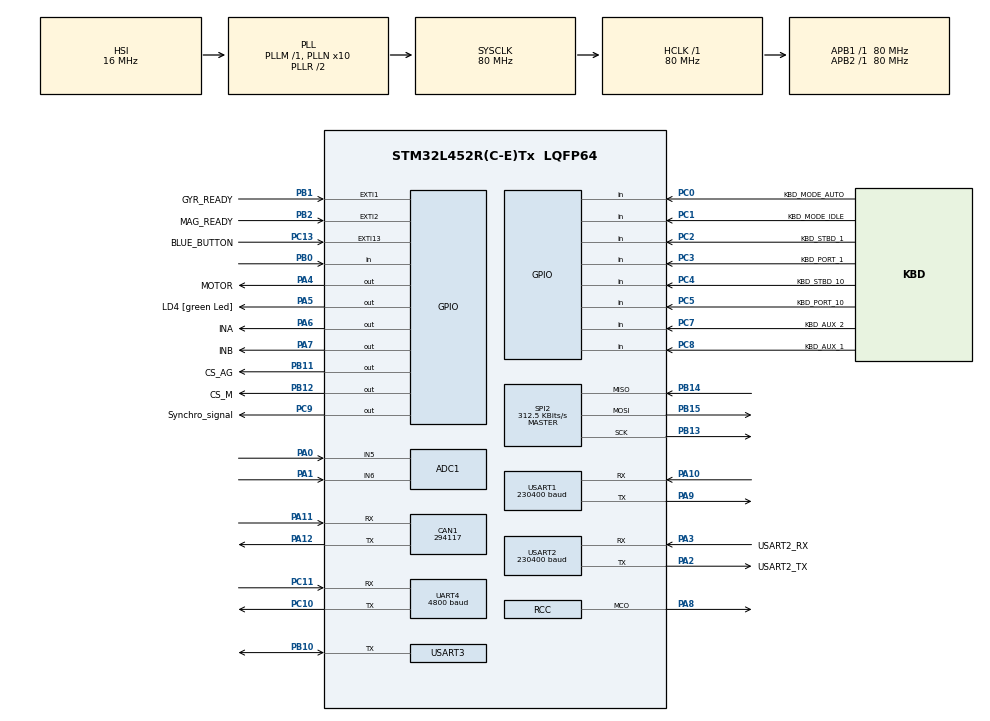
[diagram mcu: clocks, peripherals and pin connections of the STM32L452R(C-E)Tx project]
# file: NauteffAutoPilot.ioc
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ADC1.Channel-1\#ChannelRegularConversion=ADC_CHANNEL_5
ADC1.Channel-2\#ChannelRegularConversion=ADC_CHANNEL_6
ADC1.DMAContinuousRequests=ENABLE
ADC1.EOCSelection=ADC_EOC_SEQ_CONV
ADC1.ExternalTrigConv=ADC_EXTERNALTRIG_T3_TRGO
ADC1.NbrOfConversion=2
ADC1.NbrOfConversionFlag=1
ADC1.OffsetNumber-1\#ChannelRegularConversion=ADC_OFFSET_NONE
ADC1.OffsetNumber-2\#ChannelRegularConversion=ADC_OFFSET_NONE
ADC1.Rank-1\#ChannelRegularConversion=1
ADC1.Rank-2\#ChannelRegularConversion=2
ADC1.SamplingTime-1\#ChannelRegularConversion=ADC_SAMPLETIME_47CYCLES_5
ADC1.SamplingTime-2\#ChannelRegularConversion=ADC_SAMPLETIME_47CYCLES_5
ADC1.master=1
CAN1.BS1=CAN_BS1_8TQ
CAN1.BS2=CAN_BS2_8TQ
CAN1.CalculateBaudRate=294117
CAN1.CalculateTimeBit=3400
CAN1.CalculateTimeQuantum=200.0
Dma.ADC1.4.Direction=DMA_PERIPH_TO_MEMORY
Dma.ADC1.4.Instance=DMA1_Channel1
Dma.ADC1.4.MemDataAlignment=DMA_MDATAALIGN_HALFWORD
Dma.ADC1.4.MemInc=DMA_MINC_ENABLE
Dma.ADC1.4.Mode=DMA_CIRCULAR
Dma.ADC1.4.PeriphDataAlignment=DMA_PDATAALIGN_HALFWORD
Dma.ADC1.4.PeriphInc=DMA_PINC_DISABLE
Dma.ADC1.4.Priority=DMA_PRIORITY_LOW
Dma.Request0=USART2_RX
Dma.Request1=USART2_TX
Dma.Request2=USART1_RX
Dma.Request3=USART1_TX
Dma.Request4=ADC1
Dma.Request5=SPI2_RX
Dma.Request6=SPI2_TX
Dma.Request7=UART4_RX
Dma.Request8=UART4_TX
Dma.SPI2_RX.5.Direction=DMA_PERIPH_TO_MEMORY
Dma.SPI2_RX.5.Instance=DMA1_Channel4
Dma.SPI2_RX.5.MemDataAlignment=DMA_MDATAALIGN_BYTE
Dma.SPI2_RX.5.MemInc=DMA_MINC_ENABLE
Dma.SPI2_RX.5.Mode=DMA_NORMAL
Dma.SPI2_RX.5.PeriphDataAlignment=DMA_PDATAALIGN_BYTE
Dma.SPI2_RX.5.PeriphInc=DMA_PINC_DISABLE
Dma.SPI2_RX.5.Priority=DMA_PRIORITY_LOW
Dma.SPI2_TX.6.Direction=DMA_MEMORY_TO_PERIPH
Dma.SPI2_TX.6.Instance=DMA1_Channel5
Dma.SPI2_TX.6.MemDataAlignment=DMA_MDATAALIGN_BYTE
Dma.SPI2_TX.6.MemInc=DMA_MINC_ENABLE
Dma.SPI2_TX.6.Mode=DMA_NORMAL
Dma.SPI2_TX.6.PeriphDataAlignment=DMA_PDATAALIGN_BYTE
Dma.SPI2_TX.6.PeriphInc=DMA_PINC_DISABLE
Dma.SPI2_TX.6.Priority=DMA_PRIORITY_LOW
Dma.UART4_RX.7.Direction=DMA_PERIPH_TO_MEMORY
Dma.UART4_RX.7.Instance=DMA2_Channel5
Dma.UART4_RX.7.MemDataAlignment=DMA_MDATAALIGN_BYTE
Dma.UART4_RX.7.MemInc=DMA_MINC_ENABLE
Dma.UART4_RX.7.Mode=DMA_NORMAL
Dma.UART4_RX.7.PeriphDataAlignment=DMA_PDATAALIGN_BYTE
Dma.UART4_RX.7.PeriphInc=DMA_PINC_DISABLE
Dma.UART4_RX.7.Priority=DMA_PRIORITY_LOW
Dma.UART4_TX.8.Direction=DMA_MEMORY_TO_PERIPH
Dma.UART4_TX.8.Instance=DMA2_Channel3
Dma.UART4_TX.8.MemDataAlignment=DMA_MDATAALIGN_BYTE
Dma.UART4_TX.8.MemInc=DMA_MINC_ENABLE
Dma.UART4_TX.8.Mode=DMA_NORMAL
Dma.UART4_TX.8.PeriphDataAlignment=DMA_PDATAALIGN_BYTE
Dma.UART4_TX.8.PeriphInc=DMA_PINC_DISABLE
Dma.UART4_TX.8.Priority=DMA_PRIORITY_LOW
Dma.USART1_RX.2.Direction=DMA_PERIPH_TO_MEMORY
Dma.USART1_RX.2.Instance=DMA2_Channel7
Dma.USART1_RX.2.MemDataAlignment=DMA_MDATAALIGN_BYTE
Dma.USART1_RX.2.MemInc=DMA_MINC_ENABLE
Dma.USART1_RX.2.Mode=DMA_NORMAL
Dma.USART1_RX.2.PeriphDataAlignment=DMA_PDATAALIGN_BYTE
Dma.USART1_RX.2.PeriphInc=DMA_PINC_DISABLE
Dma.USART1_RX.2.Priority=DMA_PRIORITY_LOW
Dma.USART1_TX.3.Direction=DMA_MEMORY_TO_PERIPH
Dma.USART1_TX.3.Instance=DMA2_Channel6
Dma.USART1_TX.3.MemDataAlignment=DMA_MDATAALIGN_BYTE
Dma.USART1_TX.3.MemInc=DMA_MINC_ENABLE
Dma.USART1_TX.3.Mode=DMA_NORMAL
Dma.USART1_TX.3.PeriphDataAlignment=DMA_PDATAALIGN_BYTE
Dma.USART1_TX.3.PeriphInc=DMA_PINC_DISABLE
Dma.USART1_TX.3.Priority=DMA_PRIORITY_LOW
Dma.USART2_RX.0.Direction=DMA_PERIPH_TO_MEMORY
Dma.USART2_RX.0.Instance=DMA1_Channel6
Dma.USART2_RX.0.MemDataAlignment=DMA_MDATAALIGN_BYTE
Dma.USART2_RX.0.MemInc=DMA_MINC_ENABLE
Dma.USART2_RX.0.Mode=DMA_NORMAL
Dma.USART2_RX.0.PeriphDataAlignment=DMA_PDATAALIGN_BYTE
Dma.USART2_RX.0.PeriphInc=DMA_PINC_DISABLE
Dma.USART2_RX.0.Priority=DMA_PRIORITY_LOW
Dma.USART2_TX.1.Direction=DMA_MEMORY_TO_PERIPH
Dma.USART2_TX.1.Instance=DMA1_Channel7
Dma.USART2_TX.1.MemDataAlignment=DMA_MDATAALIGN_BYTE
Dma.USART2_TX.1.MemInc=DMA_MINC_ENABLE
Dma.USART2_TX.1.Mode=DMA_NORMAL
Dma.USART2_TX.1.PeriphDataAlignment=DMA_PDATAALIGN_BYTE
Dma.USART2_TX.1.PeriphInc=DMA_PINC_DISABLE
Dma.USART2_TX.1.Priority=DMA_PRIORITY_LOW
FREERTOS.Tasks01=defaultTask,24,128,StartDefaultTask,Default,NULL,Dynamic,NULL,NULL
FREERTOS.configTOTAL_HEAP_SIZE=65536
Mcu.Family=STM32L4
Mcu.Name=STM32L452R(C-E)Tx
Mcu.Package=LQFP64
NVIC.ADC1_IRQn=true\:5\:0\:false\:false\:true\:true\:true\:true\:true
NVIC.DMA1_Channel1_IRQn=true\:5\:0\:false\:false\:true\:true\:false\:true\:true
NVIC.DMA1_Channel4_IRQn=true\:5\:0\:false\:false\:true\:true\:false\:true\:true
NVIC.DMA1_Channel5_IRQn=true\:5\:0\:false\:false\:true\:true\:false\:true\:true
NVIC.DMA1_Channel6_IRQn=true\:5\:0\:false\:false\:true\:true\:false\:true\:true
NVIC.DMA1_Channel7_IRQn=true\:5\:0\:false\:false\:true\:true\:false\:true\:true
NVIC.DMA2_Channel3_IRQn=true\:5\:0\:false\:false\:true\:true\:false\:true\:true
NVIC.DMA2_Channel5_IRQn=true\:5\:0\:false\:false\:true\:true\:false\:true\:true
NVIC.DMA2_Channel6_IRQn=true\:5\:0\:false\:false\:true\:false\:false\:true\:true
NVIC.DMA2_Channel7_IRQn=true\:5\:0\:false\:false\:true\:false\:false\:true\:true
NVIC.EXTI1_IRQn=true\:5\:0\:false\:false\:true\:true\:true\:true\:false
NVIC.EXTI2_IRQn=true\:5\:0\:false\:false\:true\:true\:true\:true\:false
NVIC.PriorityGroup=NVIC_PRIORITYGROUP_4
NVIC.SPI2_IRQn=true\:5\:0\:false\:false\:true\:true\:true\:true\:true
NVIC.TIM2_IRQn=true\:0\:0\:false\:false\:true\:false\:false\:true\:true
NVIC.TimeBase=TIM2_IRQn
NVIC.TimeBaseIP=TIM2
NVIC.USART1_IRQn=true\:5\:0\:false\:false\:true\:true\:true\:true\:true
NVIC.USART2_IRQn=true\:5\:0\:false\:false\:true\:true\:true\:true\:true
PA0.Signal=ADCx_IN5
PA1.Signal=ADCx_IN6
PA10.Mode=Asynchronous
PA10.Signal=USART1_RX
PA11.Mode=CAN_Activate
PA11.Signal=CAN1_RX
PA12.Mode=CAN_Activate
PA12.Signal=CAN1_TX
PA13\ (JTMS/SWDIO).GPIO_Label=TMS
PA13\ (JTMS/SWDIO).Mode=Serial_Wire
PA13\ (JTMS/SWDIO).Signal=SYS_JTMS-SWDIO
PA14\ (JTCK/SWCLK).GPIO_Label=TCK
PA14\ (JTCK/SWCLK).Mode=Serial_Wire
PA14\ (JTCK/SWCLK).Signal=SYS_JTCK-SWCLK
PA2.GPIO_Label=USART2_TX
PA2.GPIO_Mode=GPIO_MODE_AF_PP
PA2.GPIO_PuPd=GPIO_NOPULL
PA2.GPIO_Speed=GPIO_SPEED_FREQ_VERY_HIGH
PA2.Mode=Asynchronous
PA2.Signal=USART2_TX
PA3.GPIO_Label=USART2_RX
PA3.GPIO_Mode=GPIO_MODE_AF_PP
PA3.GPIO_PuPd=GPIO_NOPULL
PA3.GPIO_Speed=GPIO_SPEED_FREQ_VERY_HIGH
PA3.Mode=Asynchronous
PA3.Signal=USART2_RX
PA4.GPIO_Label=MOTOR
PA4.Signal=GPIO_Output
PA5.GPIO_Label=LD4 [green Led]
PA5.GPIO_ModeDefaultOutputPP=GPIO_MODE_OUTPUT_PP
PA5.GPIO_PuPd=GPIO_NOPULL
PA5.GPIO_Speed=GPIO_SPEED_FREQ_LOW
PA5.Signal=GPIO_Output
PA6.GPIO_Label=INA
PA6.Signal=GPIO_Output
PA7.GPIO_Label=INB
PA7.Signal=GPIO_Output
PA8.Mode=Clock-out
PA8.Signal=RCC_MCO
PA9.Mode=Asynchronous
PA9.Signal=USART1_TX
PB0.Signal=GPIO_Input
PB1.GPIO_Label=GYR_READY
PB1.GPIO_PuPd=GPIO_NOPULL
PB1.Signal=GPXTI1
PB10.Mode=Half_duplex(single_wire_mode)
PB10.Signal=USART3_TX
PB11.GPIO_Label=CS_AG
PB11.GPIO_Speed=GPIO_SPEED_FREQ_HIGH
PB11.PinState=GPIO_PIN_SET
PB11.Signal=GPIO_Output
PB12.GPIO_Label=CS_M
PB12.GPIO_Speed=GPIO_SPEED_FREQ_HIGH
PB12.PinState=GPIO_PIN_SET
PB12.Signal=GPIO_Output
PB13.Mode=Full_Duplex_Master
PB13.Signal=SPI2_SCK
PB14.Mode=Full_Duplex_Master
PB14.Signal=SPI2_MISO
PB15.Mode=Full_Duplex_Master
PB15.Signal=SPI2_MOSI
PB2.GPIO_Label=MAG_READY
PB2.GPIO_PuPd=GPIO_NOPULL
PB2.Signal=GPXTI2
PB3\ (JTDO/TRACESWO).GPIO_Label=SWO
PB3\ (JTDO/TRACESWO).Signal=SYS_JTDO-SWO
PC0.GPIO_Label=KBD_MODE_AUTO 
PC0.GPIO_PuPd=GPIO_PULLUP
PC0.Signal=GPIO_Input
PC1.GPIO_Label=KBD_MODE_IDLE
PC1.GPIO_PuPd=GPIO_PULLUP
PC1.Signal=GPIO_Input
PC10.Mode=Asynchronous
PC10.Signal=UART4_TX
PC11.Mode=Asynchronous
PC11.Signal=UART4_RX
PC13.GPIO_Label=BLUE_BUTTON
PC13.Signal=GPXTI13
PC14-OSC32_IN\ (PC14).Mode=LSE-External-Oscillator
PC14-OSC32_IN\ (PC14).Signal=RCC_OSC32_IN
PC15-OSC32_OUT\ (PC15).Mode=LSE-External-Oscillator
PC15-OSC32_OUT\ (PC15).Signal=RCC_OSC32_OUT
PC2.GPIO_Label=KBD_STBD_1
PC2.GPIO_PuPd=GPIO_PULLUP
PC2.Signal=GPIO_Input
PC3.GPIO_Label=KBD_PORT_1
PC3.GPIO_PuPd=GPIO_PULLUP
PC3.Signal=GPIO_Input
PC4.GPIO_Label=KBD_STBD_10
PC4.GPIO_PuPd=GPIO_PULLUP
PC4.Signal=GPIO_Input
PC5.GPIO_Label=KBD_PORT_10
PC5.GPIO_PuPd=GPIO_PULLUP
PC5.Signal=GPIO_Input
PC6.Signal=S_TIM3_CH1
PC7.GPIO_Label=KBD_AUX_2
PC7.GPIO_PuPd=GPIO_PULLUP
PC7.Signal=GPIO_Input
PC8.GPIO_Label=KBD_AUX_1
PC8.GPIO_PuPd=GPIO_PULLUP
PC8.Signal=GPIO_Input
PC9.GPIO_Label=Synchro_signal
PC9.GPIO_Speed=GPIO_SPEED_FREQ_HIGH
PC9.Signal=GPIO_Output
PH0-OSC_IN\ (PH0).Signal=RCC_OSC_IN
PH1-OSC_OUT\ (PH1).Signal=RCC_OSC_OUT
ProjectManager.HeapSize=0x200
ProjectManager.StackSize=0x400
ProjectManager.TargetToolchain=Makefile
RCC.ADCFreq_Value=64000000
RCC.AHBFreq_Value=80000000
RCC.APB1Freq_Value=80000000
RCC.APB1TimFreq_Value=80000000
RCC.APB2Freq_Value=80000000
RCC.APB2TimFreq_Value=80000000
RCC.CortexFreq_Value=80000000
RCC.HCLKFreq_Value=80000000
RCC.HSE_VALUE=8000000
RCC.HSI48_VALUE=48000000
RCC.HSI_VALUE=16000000
RCC.MSI_VALUE=4000000
RCC.PLLN=10
RCC.PLLSourceVirtual=RCC_PLLSOURCE_HSI
RCC.PREFETCH_ENABLE=1
RCC.RCC_MCODiv=RCC_MCODIV_16
RCC.SYSCLKFreq_VALUE=80000000
RCC.SYSCLKSource=RCC_SYSCLKSOURCE_PLLCLK
RCC.USBFreq_Value=64000000
RCC.VCOOutputFreq_Value=160000000
SH.ADCx_IN5.0=ADC1_IN5,IN5-Single-Ended
SH.ADCx_IN6.0=ADC1_IN6,IN6-Single-Ended
SH.S_TIM3_CH1.0=TIM3_CH1
SPI2.BaudRatePrescaler=SPI_BAUDRATEPRESCALER_256
SPI2.CalculateBaudRate=312.5 KBits/s
SPI2.DataSize=SPI_DATASIZE_8BIT
SPI2.Direction=SPI_DIRECTION_2LINES
SPI2.Mode=SPI_MODE_MASTER
SPI2.VirtualType=VM_MASTER
TIM3.AutoReloadPreload=TIM_AUTORELOAD_PRELOAD_DISABLE
TIM3.Period=9999
TIM3.Prescaler=79
TIM3.TIM_MasterOutputTrigger=TIM_TRGO_UPDATE
UART4.BaudRate=4800
USART1.BaudRate=230400
USART1.StopBits=STOPBITS_1
USART1.VirtualMode-Asynchronous=VM_ASYNC
USART2.BaudRate=230400
USART2.VirtualMode-Asynchronous=VM_ASYNC
USART3.VirtualMode-Half_duplex(single_wire_mode)=VM_ASYNC
VP_FREERTOS_VS_CMSIS_V2.Mode=CMSIS_V2
VP_SYS_VS_tim2.Mode=TIM2
VP_TIM3_VS_ClockSourceINT.Mode=Internal
board=NUCLEO-L452RE

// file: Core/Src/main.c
/* USER CODE BEGIN Header */
/**
  ******************************************************************************
  * @file           : main.c
  * @brief          : Main program body
  ******************************************************************************
  * @attention
  *
  * Copyright (c) 2025 STMicroelectronics.
  * All rights reserved.
  *
  * This software is licensed under terms that can be found in the LICENSE file
  * in the root directory of this software component.
  * If no LICENSE file comes with this software, it is provided AS-IS.
  *
  ******************************************************************************
  */
/* USER CODE END Header */
#include "main.h"
#include "cmsis_os.h"

/* USER CODE BEGIN Includes */
#include "apmain.h"

/* USER CODE END Includes */

ADC_HandleTypeDef hadc1;
DMA_HandleTypeDef hdma_adc1;

CAN_HandleTypeDef hcan1;

SPI_HandleTypeDef hspi2;
DMA_HandleTypeDef hdma_spi2_rx;
DMA_HandleTypeDef hdma_spi2_tx;

TIM_HandleTypeDef htim3;

UART_HandleTypeDef huart4;
UART_HandleTypeDef huart1;
UART_HandleTypeDef huart2;
UART_HandleTypeDef huart3;
DMA_HandleTypeDef hdma_uart4_rx;
DMA_HandleTypeDef hdma_uart4_tx;
DMA_HandleTypeDef hdma_usart1_rx;
DMA_HandleTypeDef hdma_usart1_tx;
DMA_HandleTypeDef hdma_usart2_rx;
DMA_HandleTypeDef hdma_usart2_tx;

/* Definitions for defaultTask */
osThreadId_t defaultTaskHandle;
const osThreadAttr_t defaultTask_attributes = {
  .name = "defaultTask",
  .stack_size = 128 * 4,
  .priority = (osPriority_t) osPriorityNormal,
};

void SystemClock_Config(void);
static void MX_GPIO_Init(void);
static void MX_DMA_Init(void);
static void MX_USART2_UART_Init(void);
static void MX_USART1_UART_Init(void);
static void MX_ADC1_Init(void);
static void MX_TIM3_Init(void);
static void MX_SPI2_Init(void);
static void MX_UART4_Init(void);
static void MX_USART3_UART_Init(void);
static void MX_CAN1_Init(void);
void StartDefaultTask(void *argument);

int main(void)
{

  /* MCU Configuration--------------------------------------------------------*/

  /* Reset of all peripherals, Initializes the Flash interface and the Systick. */
  HAL_Init();

  /* Configure the system clock */
  SystemClock_Config();

  /* Initialize all configured peripherals */
  MX_GPIO_Init();
  MX_DMA_Init();
  MX_USART2_UART_Init();
  MX_USART1_UART_Init();
  MX_ADC1_Init();
  MX_TIM3_Init();
  MX_SPI2_Init();
  MX_UART4_Init();
  MX_USART3_UART_Init();
  MX_CAN1_Init();
  /* USER CODE BEGIN 2 */

  apmain();

  /* USER CODE END 2 */

  /* Init scheduler */
  osKernelInitialize();

  /* Create the thread(s) */
  /* creation of defaultTask */
  defaultTaskHandle = osThreadNew(StartDefaultTask, NULL, &defaultTask_attributes);

  /* Start scheduler */
  osKernelStart();

  /* We should never get here as control is now taken by the scheduler */

  /* Infinite loop */
  while (1)
  {

  }
}

void SystemClock_Config(void)
{
  RCC_OscInitTypeDef RCC_OscInitStruct = {0};
  RCC_ClkInitTypeDef RCC_ClkInitStruct = {0};

  /** Configure the main internal regulator output voltage
  */
  if (HAL_PWREx_ControlVoltageScaling(PWR_REGULATOR_VOLTAGE_SCALE1) != HAL_OK)
  {
    Error_Handler();
  }

  /** Initializes the RCC Oscillators according to the specified parameters
  * in the RCC_OscInitTypeDef structure.
  */
  RCC_OscInitStruct.OscillatorType = RCC_OSCILLATORTYPE_HSI;
  RCC_OscInitStruct.HSIState = RCC_HSI_ON;
  RCC_OscInitStruct.HSICalibrationValue = 64;
  RCC_OscInitStruct.PLL.PLLState = RCC_PLL_ON;
  RCC_OscInitStruct.PLL.PLLSource = RCC_PLLSOURCE_HSI;
  RCC_OscInitStruct.PLL.PLLM = 1;
  RCC_OscInitStruct.PLL.PLLN = 10;
  RCC_OscInitStruct.PLL.PLLP = RCC_PLLP_DIV7;
  RCC_OscInitStruct.PLL.PLLQ = RCC_PLLQ_DIV2;
  RCC_OscInitStruct.PLL.PLLR = RCC_PLLR_DIV2;
  if (HAL_RCC_OscConfig(&RCC_OscInitStruct) != HAL_OK)
  {
    Error_Handler();
  }

  /** Initializes the CPU, AHB and APB buses clocks
  */
  RCC_ClkInitStruct.ClockType = RCC_CLOCKTYPE_HCLK|RCC_CLOCKTYPE_SYSCLK
                              |RCC_CLOCKTYPE_PCLK1|RCC_CLOCKTYPE_PCLK2;
  RCC_ClkInitStruct.SYSCLKSource = RCC_SYSCLKSOURCE_PLLCLK;
  RCC_ClkInitStruct.AHBCLKDivider = RCC_SYSCLK_DIV1;
  RCC_ClkInitStruct.APB1CLKDivider = RCC_HCLK_DIV1;
  RCC_ClkInitStruct.APB2CLKDivider = RCC_HCLK_DIV1;

  if (HAL_RCC_ClockConfig(&RCC_ClkInitStruct, FLASH_LATENCY_4) != HAL_OK)
  {
    Error_Handler();
  }
  HAL_RCC_MCOConfig(RCC_MCO1, RCC_MCO1SOURCE_SYSCLK, RCC_MCODIV_16);
}

static void MX_ADC1_Init(void)
{

  ADC_ChannelConfTypeDef sConfig = {0};

  /** Common config
  */
  hadc1.Instance = ADC1;
  hadc1.Init.ClockPrescaler = ADC_CLOCK_ASYNC_DIV1;
  hadc1.Init.Resolution = ADC_RESOLUTION_12B;
  hadc1.Init.DataAlign = ADC_DATAALIGN_RIGHT;
  hadc1.Init.ScanConvMode = ADC_SCAN_ENABLE;
  hadc1.Init.EOCSelection = ADC_EOC_SEQ_CONV;
  hadc1.Init.LowPowerAutoWait = DISABLE;
  hadc1.Init.ContinuousConvMode = DISABLE;
  hadc1.Init.NbrOfConversion = 2;
  hadc1.Init.DiscontinuousConvMode = DISABLE;
  hadc1.Init.ExternalTrigConv = ADC_EXTERNALTRIG_T3_TRGO;
  hadc1.Init.ExternalTrigConvEdge = ADC_EXTERNALTRIGCONVEDGE_RISING;
  hadc1.Init.DMAContinuousRequests = ENABLE;
  hadc1.Init.Overrun = ADC_OVR_DATA_PRESERVED;
  hadc1.Init.OversamplingMode = DISABLE;
  if (HAL_ADC_Init(&hadc1) != HAL_OK)
  {
    Error_Handler();
  }

  /** Configure Regular Channel
  */
  sConfig.Channel = ADC_CHANNEL_5;
  sConfig.Rank = ADC_REGULAR_RANK_1;
  sConfig.SamplingTime = ADC_SAMPLETIME_47CYCLES_5;
  sConfig.SingleDiff = ADC_SINGLE_ENDED;
  sConfig.OffsetNumber = ADC_OFFSET_NONE;
  sConfig.Offset = 0;
  if (HAL_ADC_ConfigChannel(&hadc1, &sConfig) != HAL_OK)
  {
    Error_Handler();
  }

  /** Configure Regular Channel
  */
  sConfig.Channel = ADC_CHANNEL_6;
  sConfig.Rank = ADC_REGULAR_RANK_2;
  if (HAL_ADC_ConfigChannel(&hadc1, &sConfig) != HAL_OK)
  {
    Error_Handler();
  }

}

static void MX_CAN1_Init(void)
{

  hcan1.Instance = CAN1;
  hcan1.Init.Prescaler = 16;
  hcan1.Init.Mode = CAN_MODE_NORMAL;
  hcan1.Init.SyncJumpWidth = CAN_SJW_1TQ;
  hcan1.Init.TimeSeg1 = CAN_BS1_8TQ;
  hcan1.Init.TimeSeg2 = CAN_BS2_8TQ;
  hcan1.Init.TimeTriggeredMode = DISABLE;
  hcan1.Init.AutoBusOff = DISABLE;
  hcan1.Init.AutoWakeUp = DISABLE;
  hcan1.Init.AutoRetransmission = DISABLE;
  hcan1.Init.ReceiveFifoLocked = DISABLE;
  hcan1.Init.TransmitFifoPriority = DISABLE;
  if (HAL_CAN_Init(&hcan1) != HAL_OK)
  {
    Error_Handler();
  }

}

static void MX_SPI2_Init(void)
{

  /* SPI2 parameter configuration*/
  hspi2.Instance = SPI2;
  hspi2.Init.Mode = SPI_MODE_MASTER;
  hspi2.Init.Direction = SPI_DIRECTION_2LINES;
  hspi2.Init.DataSize = SPI_DATASIZE_8BIT;
  hspi2.Init.CLKPolarity = SPI_POLARITY_LOW;
  hspi2.Init.CLKPhase = SPI_PHASE_1EDGE;
  hspi2.Init.NSS = SPI_NSS_SOFT;
  hspi2.Init.BaudRatePrescaler = SPI_BAUDRATEPRESCALER_256;
  hspi2.Init.FirstBit = SPI_FIRSTBIT_MSB;
  hspi2.Init.TIMode = SPI_TIMODE_DISABLE;
  hspi2.Init.CRCCalculation = SPI_CRCCALCULATION_DISABLE;
  hspi2.Init.CRCPolynomial = 7;
  hspi2.Init.CRCLength = SPI_CRC_LENGTH_DATASIZE;
  hspi2.Init.NSSPMode = SPI_NSS_PULSE_ENABLE;
  if (HAL_SPI_Init(&hspi2) != HAL_OK)
  {
    Error_Handler();
  }

}

static void MX_TIM3_Init(void)
{

  TIM_ClockConfigTypeDef sClockSourceConfig = {0};
  TIM_MasterConfigTypeDef sMasterConfig = {0};

  htim3.Instance = TIM3;
  htim3.Init.Prescaler = 79;
  htim3.Init.CounterMode = TIM_COUNTERMODE_UP;
  htim3.Init.Period = 9999;
  htim3.Init.ClockDivision = TIM_CLOCKDIVISION_DIV1;
  htim3.Init.AutoReloadPreload = TIM_AUTORELOAD_PRELOAD_DISABLE;
  if (HAL_TIM_Base_Init(&htim3) != HAL_OK)
  {
    Error_Handler();
  }
  sClockSourceConfig.ClockSource = TIM_CLOCKSOURCE_INTERNAL;
  if (HAL_TIM_ConfigClockSource(&htim3, &sClockSourceConfig) != HAL_OK)
  {
    Error_Handler();
  }
  sMasterConfig.MasterOutputTrigger = TIM_TRGO_UPDATE;
  sMasterConfig.MasterSlaveMode = TIM_MASTERSLAVEMODE_DISABLE;
  if (HAL_TIMEx_MasterConfigSynchronization(&htim3, &sMasterConfig) != HAL_OK)
  {
    Error_Handler();
  }

}

static void MX_UART4_Init(void)
{

  huart4.Instance = UART4;
  huart4.Init.BaudRate = 4800;
  huart4.Init.WordLength = UART_WORDLENGTH_8B;
  huart4.Init.StopBits = UART_STOPBITS_1;
  huart4.Init.Parity = UART_PARITY_NONE;
  huart4.Init.Mode = UART_MODE_TX_RX;
  huart4.Init.HwFlowCtl = UART_HWCONTROL_NONE;
  huart4.Init.OverSampling = UART_OVERSAMPLING_16;
  huart4.Init.OneBitSampling = UART_ONE_BIT_SAMPLE_DISABLE;
  huart4.AdvancedInit.AdvFeatureInit = UART_ADVFEATURE_NO_INIT;
  if (HAL_UART_Init(&huart4) != HAL_OK)
  {
    Error_Handler();
  }

}

static void MX_USART1_UART_Init(void)
{

  huart1.Instance = USART1;
  huart1.Init.BaudRate = 230400;
  huart1.Init.WordLength = UART_WORDLENGTH_8B;
  huart1.Init.StopBits = UART_STOPBITS_1;
  huart1.Init.Parity = UART_PARITY_NONE;
  huart1.Init.Mode = UART_MODE_TX_RX;
  huart1.Init.HwFlowCtl = UART_HWCONTROL_NONE;
  huart1.Init.OverSampling = UART_OVERSAMPLING_16;
  huart1.Init.OneBitSampling = UART_ONE_BIT_SAMPLE_DISABLE;
  huart1.AdvancedInit.AdvFeatureInit = UART_ADVFEATURE_NO_INIT;
  if (HAL_UART_Init(&huart1) != HAL_OK)
  {
    Error_Handler();
  }

}

static void MX_USART2_UART_Init(void)
{

  huart2.Instance = USART2;
  huart2.Init.BaudRate = 230400;
  huart2.Init.WordLength = UART_WORDLENGTH_8B;
  huart2.Init.StopBits = UART_STOPBITS_1;
  huart2.Init.Parity = UART_PARITY_NONE;
  huart2.Init.Mode = UART_MODE_TX_RX;
  huart2.Init.HwFlowCtl = UART_HWCONTROL_NONE;
  huart2.Init.OverSampling = UART_OVERSAMPLING_16;
  huart2.Init.OneBitSampling = UART_ONE_BIT_SAMPLE_DISABLE;
  huart2.AdvancedInit.AdvFeatureInit = UART_ADVFEATURE_NO_INIT;
  if (HAL_UART_Init(&huart2) != HAL_OK)
  {
    Error_Handler();
  }

}

static void MX_USART3_UART_Init(void)
{

  huart3.Instance = USART3;
  huart3.Init.BaudRate = 115200;
  huart3.Init.WordLength = UART_WORDLENGTH_8B;
  huart3.Init.StopBits = UART_STOPBITS_1;
  huart3.Init.Parity = UART_PARITY_NONE;
  huart3.Init.Mode = UART_MODE_TX_RX;
  huart3.Init.HwFlowCtl = UART_HWCONTROL_NONE;
  huart3.Init.OverSampling = UART_OVERSAMPLING_16;
  huart3.Init.OneBitSampling = UART_ONE_BIT_SAMPLE_DISABLE;
  huart3.AdvancedInit.AdvFeatureInit = UART_ADVFEATURE_NO_INIT;
  if (HAL_HalfDuplex_Init(&huart3) != HAL_OK)
  {
    Error_Handler();
  }

}

static void MX_DMA_Init(void)
{

  /* DMA controller clock enable */
  __HAL_RCC_DMA1_CLK_ENABLE();
  __HAL_RCC_DMA2_CLK_ENABLE();

  /* DMA interrupt init */
  /* DMA1_Channel1_IRQn interrupt configuration */
  HAL_NVIC_SetPriority(DMA1_Channel1_IRQn, 5, 0);
  HAL_NVIC_EnableIRQ(DMA1_Channel1_IRQn);
  /* DMA1_Channel4_IRQn interrupt configuration */
  HAL_NVIC_SetPriority(DMA1_Channel4_IRQn, 5, 0);
  HAL_NVIC_EnableIRQ(DMA1_Channel4_IRQn);
  /* DMA1_Channel5_IRQn interrupt configuration */
  HAL_NVIC_SetPriority(DMA1_Channel5_IRQn, 5, 0);
  HAL_NVIC_EnableIRQ(DMA1_Channel5_IRQn);
  /* DMA1_Channel6_IRQn interrupt configuration */
  HAL_NVIC_SetPriority(DMA1_Channel6_IRQn, 5, 0);
  HAL_NVIC_EnableIRQ(DMA1_Channel6_IRQn);
  /* DMA1_Channel7_IRQn interrupt configuration */
  HAL_NVIC_SetPriority(DMA1_Channel7_IRQn, 5, 0);
  HAL_NVIC_EnableIRQ(DMA1_Channel7_IRQn);
  /* DMA2_Channel3_IRQn interrupt configuration */
  HAL_NVIC_SetPriority(DMA2_Channel3_IRQn, 5, 0);
  HAL_NVIC_EnableIRQ(DMA2_Channel3_IRQn);
  /* DMA2_Channel5_IRQn interrupt configuration */
  HAL_NVIC_SetPriority(DMA2_Channel5_IRQn, 5, 0);
  HAL_NVIC_EnableIRQ(DMA2_Channel5_IRQn);
  /* DMA2_Channel6_IRQn interrupt configuration */
  HAL_NVIC_SetPriority(DMA2_Channel6_IRQn, 5, 0);
  HAL_NVIC_EnableIRQ(DMA2_Channel6_IRQn);
  /* DMA2_Channel7_IRQn interrupt configuration */
  HAL_NVIC_SetPriority(DMA2_Channel7_IRQn, 5, 0);
  HAL_NVIC_EnableIRQ(DMA2_Channel7_IRQn);

}

static void MX_GPIO_Init(void)
{
  LL_EXTI_InitTypeDef EXTI_InitStruct = {0};
  LL_GPIO_InitTypeDef GPIO_InitStruct = {0};

  /* GPIO Ports Clock Enable */
  LL_AHB2_GRP1_EnableClock(LL_AHB2_GRP1_PERIPH_GPIOC);
  LL_AHB2_GRP1_EnableClock(LL_AHB2_GRP1_PERIPH_GPIOH);
  LL_AHB2_GRP1_EnableClock(LL_AHB2_GRP1_PERIPH_GPIOA);
  LL_AHB2_GRP1_EnableClock(LL_AHB2_GRP1_PERIPH_GPIOB);
  LL_AHB2_GRP1_EnableClock(LL_AHB2_GRP1_PERIPH_GPIOD);

  /**/
  LL_GPIO_ResetOutputPin(GPIOA, MOTOR_Pin|LD4_Pin|INA_Pin|INB_Pin);

  /**/
  LL_GPIO_ResetOutputPin(Synchro_signal_GPIO_Port, Synchro_signal_Pin);

  /**/
  LL_GPIO_SetOutputPin(GPIOB, CS_AG_Pin|CS_M_Pin);

  /**/
  LL_SYSCFG_SetEXTISource(LL_SYSCFG_EXTI_PORTC, LL_SYSCFG_EXTI_LINE13);

  /**/
  LL_SYSCFG_SetEXTISource(LL_SYSCFG_EXTI_PORTB, LL_SYSCFG_EXTI_LINE1);

  /**/
  LL_SYSCFG_SetEXTISource(LL_SYSCFG_EXTI_PORTB, LL_SYSCFG_EXTI_LINE2);

  /**/
  EXTI_InitStruct.Line_0_31 = LL_EXTI_LINE_13;
  EXTI_InitStruct.Line_32_63 = LL_EXTI_LINE_NONE;
  EXTI_InitStruct.LineCommand = ENABLE;
  EXTI_InitStruct.Mode = LL_EXTI_MODE_IT;
  EXTI_InitStruct.Trigger = LL_EXTI_TRIGGER_RISING;
  LL_EXTI_Init(&EXTI_InitStruct);

  /**/
  EXTI_InitStruct.Line_0_31 = LL_EXTI_LINE_1;
  EXTI_InitStruct.Line_32_63 = LL_EXTI_LINE_NONE;
  EXTI_InitStruct.LineCommand = ENABLE;
  EXTI_InitStruct.Mode = LL_EXTI_MODE_IT;
  EXTI_InitStruct.Trigger = LL_EXTI_TRIGGER_RISING;
  LL_EXTI_Init(&EXTI_InitStruct);

  /**/
  EXTI_InitStruct.Line_0_31 = LL_EXTI_LINE_2;
  EXTI_InitStruct.Line_32_63 = LL_EXTI_LINE_NONE;
  EXTI_InitStruct.LineCommand = ENABLE;
  EXTI_InitStruct.Mode = LL_EXTI_MODE_IT;
  EXTI_InitStruct.Trigger = LL_EXTI_TRIGGER_RISING;
  LL_EXTI_Init(&EXTI_InitStruct);

  /**/
  LL_GPIO_SetPinPull(BLUE_BUTTON_GPIO_Port, BLUE_BUTTON_Pin, LL_GPIO_PULL_NO);

  /**/
  LL_GPIO_SetPinPull(GYR_READY_GPIO_Port, GYR_READY_Pin, LL_GPIO_PULL_NO);

  /**/
  LL_GPIO_SetPinPull(MAG_READY_GPIO_Port, MAG_READY_Pin, LL_GPIO_PULL_NO);

  /**/
  LL_GPIO_SetPinMode(BLUE_BUTTON_GPIO_Port, BLUE_BUTTON_Pin, LL_GPIO_MODE_INPUT);

  /**/
  LL_GPIO_SetPinMode(GYR_READY_GPIO_Port, GYR_READY_Pin, LL_GPIO_MODE_INPUT);

  /**/
  LL_GPIO_SetPinMode(MAG_READY_GPIO_Port, MAG_READY_Pin, LL_GPIO_MODE_INPUT);

  /**/
  GPIO_InitStruct.Pin = KBD_MODE_AUTO_Pin|KBD_MODE_IDLE_Pin|KBD_STBD_1_Pin|KBD_PORT_1_Pin
                          |KBD_STBD_10_Pin|KBD_PORT_10_Pin|KBD_AUX_2_Pin|KBD_AUX_1_Pin;
  GPIO_InitStruct.Mode = LL_GPIO_MODE_INPUT;
  GPIO_InitStruct.Pull = LL_GPIO_PULL_UP;
  LL_GPIO_Init(GPIOC, &GPIO_InitStruct);

  /**/
  GPIO_InitStruct.Pin = MOTOR_Pin|LD4_Pin|INA_Pin|INB_Pin;
  GPIO_InitStruct.Mode = LL_GPIO_MODE_OUTPUT;
  GPIO_InitStruct.Speed = LL_GPIO_SPEED_FREQ_LOW;
  GPIO_InitStruct.OutputType = LL_GPIO_OUTPUT_PUSHPULL;
  GPIO_InitStruct.Pull = LL_GPIO_PULL_NO;
  LL_GPIO_Init(GPIOA, &GPIO_InitStruct);

  /**/
  GPIO_InitStruct.Pin = LL_GPIO_PIN_0;
  GPIO_InitStruct.Mode = LL_GPIO_MODE_INPUT;
  GPIO_InitStruct.Pull = LL_GPIO_PULL_NO;
  LL_GPIO_Init(GPIOB, &GPIO_InitStruct);

  /**/
  GPIO_InitStruct.Pin = CS_AG_Pin|CS_M_Pin;
  GPIO_InitStruct.Mode = LL_GPIO_MODE_OUTPUT;
  GPIO_InitStruct.Speed = LL_GPIO_SPEED_FREQ_HIGH;
  GPIO_InitStruct.OutputType = LL_GPIO_OUTPUT_PUSHPULL;
  GPIO_InitStruct.Pull = LL_GPIO_PULL_NO;
  LL_GPIO_Init(GPIOB, &GPIO_InitStruct);

  /**/
  GPIO_InitStruct.Pin = Synchro_signal_Pin;
  GPIO_InitStruct.Mode = LL_GPIO_MODE_OUTPUT;
  GPIO_InitStruct.Speed = LL_GPIO_SPEED_FREQ_HIGH;
  GPIO_InitStruct.OutputType = LL_GPIO_OUTPUT_PUSHPULL;
  GPIO_InitStruct.Pull = LL_GPIO_PULL_NO;
  LL_GPIO_Init(Synchro_signal_GPIO_Port, &GPIO_InitStruct);

  /**/
  GPIO_InitStruct.Pin = LL_GPIO_PIN_8;
  GPIO_InitStruct.Mode = LL_GPIO_MODE_ALTERNATE;
  GPIO_InitStruct.Speed = LL_GPIO_SPEED_FREQ_LOW;
  GPIO_InitStruct.OutputType = LL_GPIO_OUTPUT_PUSHPULL;
  GPIO_InitStruct.Pull = LL_GPIO_PULL_NO;
  GPIO_InitStruct.Alternate = LL_GPIO_AF_0;
  LL_GPIO_Init(GPIOA, &GPIO_InitStruct);

  /**/
  GPIO_InitStruct.Pin = LL_GPIO_PIN_15;
  GPIO_InitStruct.Mode = LL_GPIO_MODE_ANALOG;
  GPIO_InitStruct.Pull = LL_GPIO_PULL_NO;
  LL_GPIO_Init(GPIOA, &GPIO_InitStruct);

  /**/
  GPIO_InitStruct.Pin = LL_GPIO_PIN_12;
  GPIO_InitStruct.Mode = LL_GPIO_MODE_ANALOG;
  GPIO_InitStruct.Pull = LL_GPIO_PULL_NO;
  LL_GPIO_Init(GPIOC, &GPIO_InitStruct);

  /**/
  GPIO_InitStruct.Pin = LL_GPIO_PIN_2;
  GPIO_InitStruct.Mode = LL_GPIO_MODE_ANALOG;
  GPIO_InitStruct.Pull = LL_GPIO_PULL_NO;
  LL_GPIO_Init(GPIOD, &GPIO_InitStruct);

  /**/
  GPIO_InitStruct.Pin = LL_GPIO_PIN_4|LL_GPIO_PIN_5|LL_GPIO_PIN_6|LL_GPIO_PIN_7
                          |LL_GPIO_PIN_8|LL_GPIO_PIN_9;
  GPIO_InitStruct.Mode = LL_GPIO_MODE_ANALOG;
  GPIO_InitStruct.Pull = LL_GPIO_PULL_NO;
  LL_GPIO_Init(GPIOB, &GPIO_InitStruct);

  /**/
  GPIO_InitStruct.Pin = LL_GPIO_PIN_3;
  GPIO_InitStruct.Mode = LL_GPIO_MODE_ANALOG;
  GPIO_InitStruct.Pull = LL_GPIO_PULL_NO;
  LL_GPIO_Init(GPIOH, &GPIO_InitStruct);

  /* EXTI interrupt init*/
  NVIC_SetPriority(EXTI1_IRQn, NVIC_EncodePriority(NVIC_GetPriorityGrouping(),5, 0));
  NVIC_SetPriority(EXTI2_IRQn, NVIC_EncodePriority(NVIC_GetPriorityGrouping(),5, 0));

}

void StartDefaultTask(void *argument)
{
  for(;;)
  {
    osDelay(1);
  }
}

void HAL_TIM_PeriodElapsedCallback(TIM_HandleTypeDef *htim)
{
  if (htim->Instance == TIM2)
  {
    HAL_IncTick();
  }
}

void Error_Handler(void)
{
  __disable_irq();
  while (1)
  {
  }
}
